# PIC32CZ2051CA80100 device description
Architecture: CORTEX-M7; Family: PIC32C; Series: PIC32CZCA80
Registers are 32-bit, read-write, reset 0x0 unless marked. A register's access mark holds for its fields unless they carry their own. Offsets are from the block's base; [hi:lo] are bit positions; {n}, {i} and the like mark numbered series; 'fields as' and 'values as' point back to an identical list; <NAME> marks a mode.

## ITM — Instrumentation Trace Macrocell
Instances: ITM 0xE0041000
{0x0+4i} PORT[{i}] (i=0..31) wo reset not defined — ITM Stimulus Port Registers
  [7:0] PORT <BYTE>, [15:0] PORT <HWORD>, [31:0] PORT <WORD>
0xE00 TER reset not defined — ITM Trace Enable Register
0xE40 TPR reset not defined — ITM Trace Privilege Register
  [3:0] PRIVMASK
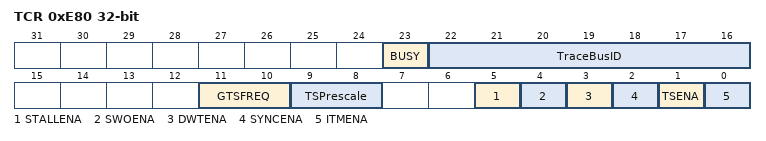
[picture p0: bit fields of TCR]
0xE80 TCR reset not defined — ITM Trace Control Register
  [23] BUSY, [22:16] TraceBusID, [11:10] GTSFREQ, [9:8] TSPrescale, [5] STALLENA, [4] SWOENA, [3] DWTENA, [2] SYNCENA, [1] TSENA, [0] ITMENA
0xEF8 IWR wo reset not defined — ITM Integration Write Register
  [0] ATVALIDM
0xEFC IRR ro reset not defined — ITM Integration Read Register
  [0] ATREADYM

## MCLK — Main Clock
Instances: MCLK 0x44052000
0x00 INTENCLR (atomic clear) — Interrupt Enable Clear
  [0] CKRDY — Clock Ready Interrupt Enable
0x04 INTENSET (atomic set) — Interrupt Enable Set
  [0] CKRDY — Clock Ready Interrupt Enable
0x08 INTFLAG reset 0x1 (atomic clear) — Interrupt Flag Status and Clear
  [0] CKRDY — Clock Ready
{0xC+4i} CLKDIV[{i}] (i=0..1) — Clock Divider Control
  [7:0] DIV — Clock Domain Division Factor
    1=Divide by 1; 2=Divide by 2; 4=Divide by 4; 8=Divide by 8; 16=Divide by 16; 32=Divide by 32; 64=Divide by 64; 128=Divide by 128
{0x3C+4i} CLKMSK[{i}] (i=0..8) — Peripheral Clock Enable Mask
  [31:0] MASK

## MCRAMC — Multi-Channel RAM Controller
Instances: MCRAMC 0x44822000
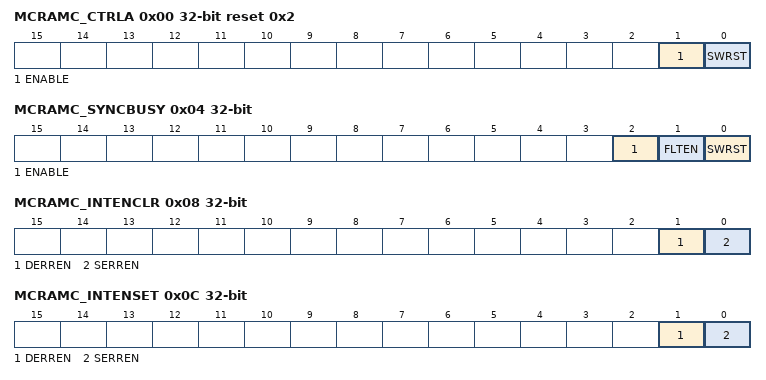
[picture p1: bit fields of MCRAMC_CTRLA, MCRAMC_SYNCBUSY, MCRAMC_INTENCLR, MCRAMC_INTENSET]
0x00 MCRAMC_CTRLA reset 0x2 — Control Enable A Register
  [1] ENABLE — ECC Decoder Enable
    0=ECC decoding is disabled; 1=ECC decoding is enabled
  [0] SWRST — Software Reset
    0=No effect; 1=Reset the MCRAMC. A software-triggered hardware reset of the MCRAMC user interface is performed.
0x04 MCRAMC_SYNCBUSY ro — Sync Busy Register
  [2] ENABLE — ECC Decoder Enable busy bit
  [1] FLTEN — Fault Injection Enabled busy bit
  [0] SWRST — Software reset busy bit
0x08 MCRAMC_INTENCLR (atomic clear) — Interrupt Enable Clear Register
  [1] DERREN — Double Bit Error Interrupt Enable, Clear
  [0] SERREN — Single Bit Error Interrupt Enable, Clear
0x0C MCRAMC_INTENSET (atomic set) — Interrupt Enable Set Register
  [1] DERREN — Double Bit Error Interrupt Enable, Set
  [0] SERREN — Single Bit Error Interrupt Enable, Set
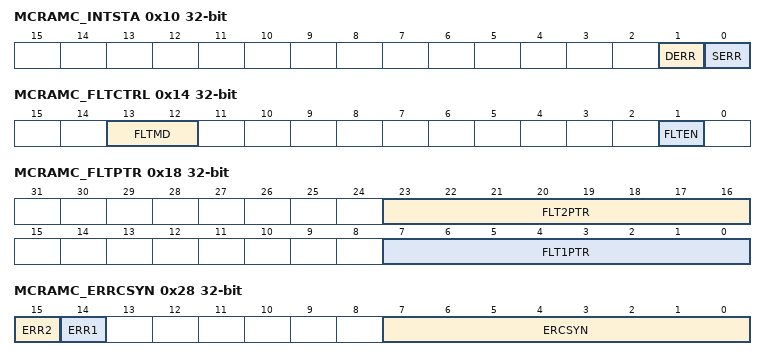
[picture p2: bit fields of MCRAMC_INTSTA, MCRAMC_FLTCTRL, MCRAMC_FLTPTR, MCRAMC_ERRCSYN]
0x10 MCRAMC_INTSTA (atomic clear) — Interrupt Status Register
  [1] DERR — Double Bit Error
  [0] SERR — Single Bit Error
0x14 MCRAMC_FLTCTRL — Fault Injection Control Register
  [13:12] FLTMD — Fault Injection Mode
  [1] FLTEN — Fault Injection Enabled
    0=Disables fault injection; 1=Enables fault injection at FLTADR address offset as selected by FLTMD and FLTxPTR
0x18 MCRAMC_FLTPTR — Fault Injection Pointer Register
  [23:16] FLT2PTR — Double Fault Injection Bit Pointer
  [7:0] FLT1PTR — Single Fault Injection Bit Pointer
0x1C MCRAMC_FLTADR — Fault Injection Address Register
  [23:0] FLTADR — Fault Address Offset
0x20 MCRAMC_ERRCADR ro — Error Capture Address Register
  [23:0] ERCADR — ECC SECDED Error Capture Address
0x24 MCRAMC_ERRCPAR ro — Error Capture Parity Register
  [7:0] ERCPAR — ECC SECDED Error Capture Parity
0x28 MCRAMC_ERRCSYN ro — Error Capture Syndrome Register
  [15] ERR2 — ECC Double Bit Error
    0=Not a Double bit error; 1=Double bit error
  [14] ERR1 — ECC Single Bit Error
  [7:0] ERCSYN — ECC SECDED Error Capture Syndrome
    0=Not a Single bit error; 1=Single bit error

## MPU — Memory Protection Unit
Instances: MPU 0xE000ED90
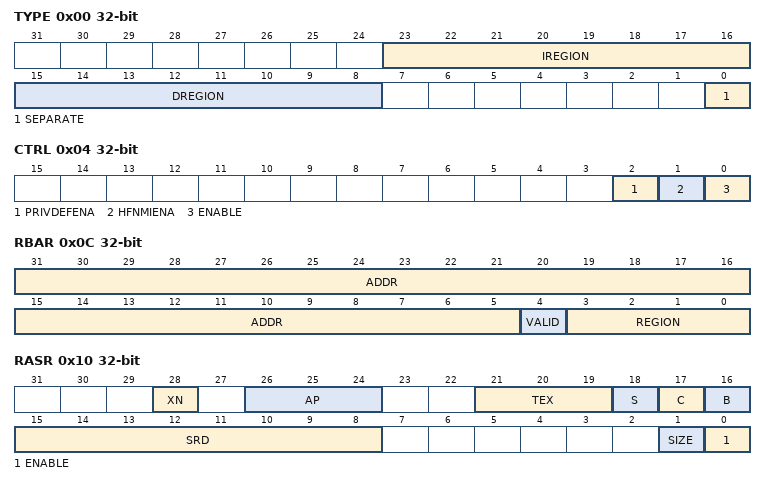
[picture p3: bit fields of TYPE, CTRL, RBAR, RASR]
0x00 TYPE ro reset not defined — MPU Type Register
  [23:16] IREGION — Number of Instruction Regions
  [15:8] DREGION — Number of Data Regions
  [0] SEPARATE — Separate instruction and Data Memory MapsRegions
0x04 CTRL — MPU Control Register
  [2] PRIVDEFENA — Enables privileged software access to default memory map
  [1] HFNMIENA — Enable Hard Fault and NMI handlers
  [0] ENABLE — MPU Enable
0x08 RNR reset not defined — MPU Region Number Register
  [7:0] REGION — Region referenced by RBAR and RASR
0x0C RBAR reset not defined — MPU Region Base Address Register
  [31:5] ADDR — Region base address
  [4] VALID — Region number valid
  [3:0] REGION — Region number
0x10 RASR reset not defined — MPU Region Attribute and Size Register
  [28] XN — Execute Never Attribute
  [26:24] AP — Access Permission
  [21:19] TEX — TEX bit
  [18] S — Shareable bit
  [17] C — Cacheable bit
  [16] B — Bufferable bit
  [15:8] SRD — Sub-region disable
  [1] SIZE — Region Size
  [0] ENABLE — Region Enable
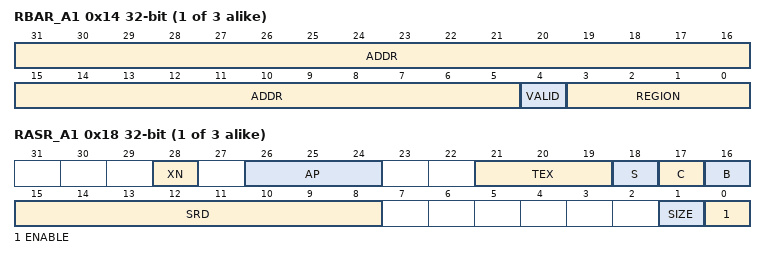
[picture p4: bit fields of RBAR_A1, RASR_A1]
{0xC+8i} RBAR_A{i} reset not defined (i=1..3) — MPU Alias {i} Region Base Address Register
  fields as RBAR
{0x10+8i} RASR_A{i} reset not defined (i=1..3) — MPU Alias {i} Region Attribute and Size Register
  fields as RASR

## Notices in the file
Copyright (c) 2021 Microchip Technology Inc.
SPDX-License-Identifier: Apache-2.0
Licensed under the Apache License, Version 2.0 (the "License");
you may not use this file except in compliance with the License.
You may obtain a copy of the License at
http://www.apache.org/licenses/LICENSE-2.0
Unless required by applicable law or agreed to in writing, software
distributed under the License is distributed on an "AS IS" BASIS,
WITHOUT WARRANTIES OR CONDITIONS OF ANY KIND, either express or implied.
See the License for the specific language governing permissions and
limitations under the License.
